# RS14100 register map
File version: 1.0
CPU: CM4 r0p1, little endian, MPU, FPU, 4 interrupt priority bits
Registers are 32-bit, read-write, reset 0x0 unless marked. A register's access mark holds for its fields unless they carry their own. Offsets are from the block's base; [hi:lo] are bit positions; 'fields as' and 'values as' point back to an identical list.

## SLEEP_FSM — This is explain the Sleep FSM registers.
Base 0x24048100
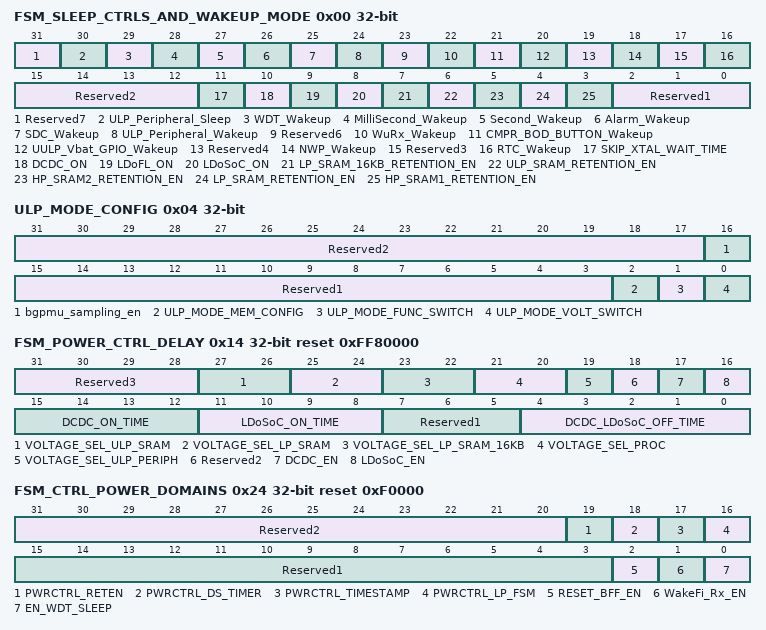
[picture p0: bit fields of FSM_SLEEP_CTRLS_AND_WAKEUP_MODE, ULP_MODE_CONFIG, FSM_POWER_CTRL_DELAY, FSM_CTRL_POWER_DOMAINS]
0x00 FSM_SLEEP_CTRLS_AND_WAKEUP_MODE — Sleep Control Signals and Wakeup source selection
  [31] Reserved7 — It is recommended to write these bits to 0.
  [30] ULP_Peripheral_Sleep — It is enable or disable ULP Peripheral Interrupt as a Sleep source.
    0=disable (Writing 0 to this disables ULP Peripheral Interrupt as a Sleep source.); 1=enable (Writing 1 to this enables ULP Peripheral Interrupt as a Sleep source.)
  [29] WDT_Wakeup — It is enable or disable WDT Interrupt as a Wakeup source.
    0=disable (Writing 0 to this disables WDT Interrupt as a Wakeup source.); 1=enable (Writing 1 to this enables WDT Interrupt as a Wakeup source.)
  [28] MilliSecond_Wakeup — It is enable or disable Milli-Second Interrupt as a Wakeup source
    0=disable (Writing 0 to this disables Milli-Second Interrupt as a Wakeup source.); 1=enable (Writing 1 to this enables Milli-Second Interrupt as a Wakeup source.)
  [27] Second_Wakeup — It is enable or disable Second Interrupt as a Wakeup source
    0=disable (Writing 0 to this disables Second Interrupt as a Wakeup source.); 1=enable (Writing 1 to this enables Second Interrupt as a Wakeup source)
  [26] Alarm_Wakeup — It is enable or disable ALARM Interrupt as a Wakeup source.
    0=disable (Writing 0 to this disables ALARM Interrupt as a Wakeup source.); 1=enable (Writing 1 to this enables ALARM Interrupt as a Wakeup source.)
  [25] SDC_Wakeup — It is enable or disable Sensor Data Collector Interrupt as a Wakeup source.
    0=disable (Writing 0 to this disables Sensor Data Collector Interrupt as a Wakeup source); 1=enable (Writing 1 to this enables Sensor Data Collector Interrupt as a Wakeup source)
  [24] ULP_Peripheral_Wakeup — It is enable or disable ULP Peripheral Interrupt as a Wakeup source
    0=disable (Writing 0 to this disables ULP Peripheral Interrupt as a Wakeup source); 1=enable (Writing 1 to this enables ULP Peripheral Interrupt as a Wakeup source)
  [23] Reserved6 — It is recommended to write these bits to 0.
  [22] WuRx_Wakeup — It is enable or disable wake-Fi Rx Interrupt as a Wakeup source
    0=disable (Writing 0 to this disables Wake-Fi Rx Interrupt as a Wakeup source.); 1=enable (Writing 1 to this enables Wake-Fi Rx Interrupt as a Wakeup source.)
  [21] CMPR_BOD_BUTTON_Wakeup — It is enable or disable 4x-Comparator/BOD/BUTTON Interrupt as a Wakeup source
    0=disable (Writing 0 to this disables 4x-Comparator/BOD/BUTTON Interrupt as a Wakeup source); 1=enable (Writing 1 to this enables 4x-Comparator/BOD/BUTTON Interrupt as a Wakeup source)
  [20] UULP_Vbat_GPIO_Wakeup — It is enable or disable UULP Vbat GPIO Interrupt as a Wakeup source
    0=disable (Writing 0 to this disables UULP Vbat GPIO Interrupt as a Wakeup source); 1=enable (Writing 1 to this enables UULP Vbat GPIO Interrupt as a Wakeup source)
  [19] Reserved4 — It is recommended to write these bits to 0.
  [18] NWP_Wakeup — It is enable or disable NWP Interrupt as a Wakeup source
    0=disable (Writing 0 to this disables RTC Interrupt as a Wakeup source); 1=enable (Writing 1 to this enables RTC Interrupt as a Wakeup source)
  [17] Reserved3 — It is recommended to write these bits to 0.
  [16] RTC_Wakeup — It is enable or disable RTC Interrupt as a Wakeup source
    values as NWP_Wakeup
  [15:12] Reserved2 — It is recommended to write these bits to 0.
  [11] SKIP_XTAL_WAIT_TIME — It is used to skips the settling time for High Frequency XTAL during wakeup.
    0=disable (Writing 0 to this includes the settling time for High Frequency XTAL during wakeup.); 1=enable (Writing 1 to this skips the settling time for High Frequency XTAL during wakeup.)
  [10] DCDC_ON — It is maintain DC-DC 1.35 on state
    0=disable (Writing 0 to this maintains LDO FL 1.8 in OFF state during Sleep.); 1=enable (Writing 1 to this maintains LDO FL 1.8 in ON state during Sleep.)
  [9] LDoFL_ON — It is maintain LDO FL 1.8 on state
    values as DCDC_ON
  [8] LDoSoC_ON — It is maintain LDO SOC 1.1 on state
    0=disable (Writing 0 to this maintains LDO SoC 1.1 in OFF state during Sleep.); 1=enable (Writing 1 to this maintains LDO SoC 1.1 in ON state during Sleep.)
  [7] LP_SRAM_16KB_RETENTION_EN — SRAM retention Control for 16KB of LP-SRAM (LP-SRAM-1, LP-SRAM-2, LP-SRAM-3, LP-SRAM-4)
    0=disable (Writing 1 to this enables Retention during sleep); 1=enable (Writing 1 to this enables Retention during sleep)
  [6] ULP_SRAM_RETENTION_EN — SRAM retention Control for 16KB of ULP-SRAM
    values as LP_SRAM_16KB_RETENTION_EN
  [5] HP_SRAM2_RETENTION_EN — SRAM retention Control for 192KB of HP-SRAM2
    values as LP_SRAM_16KB_RETENTION_EN
  [4] LP_SRAM_RETENTION_EN — SRAM retention Control for 112KB of LP-SRAM (LP-SRAM-5, LP-SRAM-6, LP-SRAM-7)
    values as LP_SRAM_16KB_RETENTION_EN
  [3] HP_SRAM1_RETENTION_EN — SRAM retention Control for 64KB of HP-SRAM1
    values as LP_SRAM_16KB_RETENTION_EN
  [2:0] Reserved1 — It is recommended to write these bits to 0.
0x04 ULP_MODE_CONFIG — Configuration for Ultra Low-Power Mode of the processor (PS2 State)
  [31:17] Reserved2 — It is recommended to write these bits to 0.
  [16] bgpmu_sampling_en — Controls the mode of Band-Gap for DC-DC 1.35 during PS2 state.
    0=disable (Writing 0 to this disables sampling mode of Band-Gap. This is described in Power Management Section.); 1=enable (Writing 1 to this enables sampling mode of Band-Gap. This is described in Power Management Section.)
  [15:3] Reserved1 — It is recommended to write these bits to 0.
  [2] ULP_MODE_MEM_CONFIG — Its enable or disable maximum of 32KB of LP-SRAM for operation in PS2 state
    0=disable (Writing 0 to this enables a maximum of 128KB of LP-SRAM for operation in PS2 state.); 1=enable (Writing 1 to this enables a maximum of 32KB of LP-SRAM for operation in PS2 state.)
  [1] ULP_MODE_FUNC_SWITCH — Enable functional switching for PS2-PS4/PS3 and PS4/PS3-PS2 state transitions
    0=disable (Writing 0 to this disables functional switching for PS2-PS4/PS3 state transition); 1=enable (Writing 1 to this enables functional switching for PS4/PS3-PS2 state transition.)
  [0] ULP_MODE_VOLT_SWITCH — Enables voltage switching for PS2-PS4/PS3 and PS4/PS3-PS2 state transitions.
    0=disable (Writing 0 to this disables voltage switching for PS2-PS4/PS3 state transition); 1=enable (Writing 1 to this enables voltage switching for PS4/PS3-PS2 state transition.)
0x14 FSM_POWER_CTRL_DELAY reset 0xFF80000 — Power Control and Delay Configuration for Ultra Low-Power Mode of the processor (PS2 State)
  [31:28] Reserved3 — It is recommended to write these bits to 0.
  [27:26] VOLTAGE_SEL_ULP_SRAM — Configures the Voltage source to be used for LOW-VOLTAGE-ULPRAM Domain in PS2 state.
    0=Reserved1; 1=DC-DC 0.95; 3=LDO SoC 1.1
  [25:24] VOLTAGE_SEL_LP_SRAM — Configures the Voltage source to be used for LOW-VOLTAGE-LPRAM Domain in PS2 state.
    0=Reserved1; 1=DC-DC 0.95; 3=LDO SoC 1.1
  [23:22] VOLTAGE_SEL_LP_SRAM_16KB — Configures the Voltage source to be used for LOW-VOLTAGE-LPRAM-16KB Domain in PS2 state.
    0=LDO 0.7V; 1=DC-DC 0.95; 3=LDO SoC 1.1
  [21:20] VOLTAGE_SEL_PROC — Configures the Voltage source to be used for PROC-DOMAIN Domain in PS2 state.
    0=LDO 0.7V; 1=DC-DC 0.95; 3=LDO SoC 1.1
  [19] VOLTAGE_SEL_ULP_PERIPH — Configures the Voltage source to be used for LOW-VOLTAGE-ULPPERIPH Domain in PS2 .
    0=DC-DC 0.95; 1=LDO SoC 1.1
  [18] Reserved2 — It is recommended to write these bits to 0.
  [17] DCDC_EN — Its used to configures DC-DC 1.35 ON or OFF state during PS2.
    0=OFF (Writing 0 to this configures DC-DC 1.35 in OFF state during PS2.); 1=ON (Writing 1 to this configures DC-DC 1.35 to ON state during PS2.)
  [16] LDoSoC_EN — Its used to configures LDO Soc 1.1 ON or OFF state during PS2.
    0=OFF (Writing 0 to this configures LDO SoC 1.1 in OFF state during PS2.); 1=ON (Writing 1 to this configures LDO SoC 1.1 to ON state during PS2.)
  [15:12] DCDC_ON_TIME — Configures the time for switching ON the DC-DC 1.35 during transition from PS2 to PS4 state.
    0=Configure switching 50us ON time of DC-DC; 1=Configure switching 100us ON time of DC-DC; 2=Configure switching 200us ON time of DC-DC; 3=Configure switching 300us ON time of DC-DC; 4=Configure switching 400us ON time of DC-DC; 5=Configure switching 500us ON time of DC-DC; 6=Configure switching 600us ON time of DC-DC; 7=Configure switching 700us ON time of DC-DC; 8=Configure switching 800us ON time of DC-DC; 9=Configure switching 900us ON time of DC-DC; 10=Configure switching 1000us ON time of DC-DC; 11=Configure switching 1100us ON time of DC-DC; 12=Configure switching 1200us ON time of DC-DC; 13=Configure switching 1300us ON time of DC-DC; 14=Configure switching 1400us ON time of DC-DC; 15=Configure switching 1400us ON time of DC-DC
  [11:8] LDoSoC_ON_TIME — Configures the time for switching ON the LDO SoC 1.1 during transition from PS2 to PS4 state.
    0=Configure switching 50us ON time of LDO Soc; 1=Configure switching 100us ON time of LDO Soc; 2=Configure switching 200us ON time of LDO Soc; 3=Configure switching 300us ON time of LDO Soc; 4=Configure switching 400us ON time of LDO Soc; 5=Configure switching 500us ON time of LDO Soc; 6=Configure switching 600us ON time of LDO Soc; 7=Configure switching 700us ON time of LDO Soc; 8=Configure switching 800us ON time of LDO Soc; 9=Configure switching 900us ON time of LDO Soc; 10=Configure switching 1000us ON time of LDO Soc; 11=Configure switching 1100us ON time of LDO Soc; 12=Configure switching 1200us ON time of LDO Soc; 13=Configure switching 1300us ON time of LDO Soc; 14=Configure switching 1400us ON time of LDO Soc; 15=Configure switching 1400us ON time of LDO Soc
  [7:5] Reserved1 — It is recommended to write these bits to 0.
  [4:0] DCDC_LDoSoC_OFF_TIME — Configures the time for switching OFF the LDO SoC 1.1 and the DC-DC 1.35 during transition from PS2 to PS4 state.
0x24 FSM_CTRL_POWER_DOMAINS reset 0xF0000 — Power Domains Controlled by Sleep FSM.
  [31:20] Reserved2 — It is recommended to write these bits to 0.
  [19] PWRCTRL_RETEN — Its enable or disable Power to Retention Flops during SHIP state.These Flops are used for storing Chip Configuration.
    0=disable (Writing 0 to this disables Power to Retention Flops during SHIP state. These Flops are used for storing Chip Configuration.); 1=enable (Writing 1 to this enables Power to Retention Flops during SHIP state. These Flops are used for storing Chip Configuration.)
  [18] PWRCTRL_DS_TIMER — Its enable or disable Power to DEEP SLEEP Timer.
    0=disable (Writing 0 to this disables Power to DEEP SLEEP Timer.); 1=enable (Writing 1 to this enables Power to DEEP SLEEP Timer.)
  [17] PWRCTRL_TIMESTAMP — Its enable or disable Power to TIMESTAMP.
    0=disable (Writing 0 to this disables Power to TIMESTAMP.); 1=enable (Writing 1 to this enables Power to TIMESTAMP.)
  [16] PWRCTRL_LP_FSM — Its enable or disable Power to Low-Power FSM.
    0=disable (Writing 0 to this disables Power to Low-Power FSM.); 1=enable (Writing 1 to this enables Power to Low-Power FSM.)
  [15:3] Reserved1 — It is recommended to write these bits to 0.
  [2] RESET_BFF_EN — Its enable or disable reset of Power Domain Control Battery FF's on wakeup.
    0=disable (Writing 0 to this disables reset of Power Domain Control Battery FF's on wakeup.); 1=enable (Writing 1 to this enables reset of Power Domain Control Battery FF's on wakeup)
  [1] WakeFi_Rx_EN — Its enable or disable detection of On-Air Pattern using Wake-Fi Rx.
    0=disable (Writing 0 to this disables detection of On-Air Pattern using Wake-Fi Rx.); 1=enable (Writing 1 to this enables detection of On-Air Pattern using Wake-Fi Rx.)
  [0] EN_WDT_SLEEP — Its enable or disable WDT during Sleep/Shutdown states.
    0=disable (Writing 0 to this enables WDT during Sleep/Shutdown states.); 1=enable (Writing 1 to this enables WDT during Sleep/Shutdown states.)
